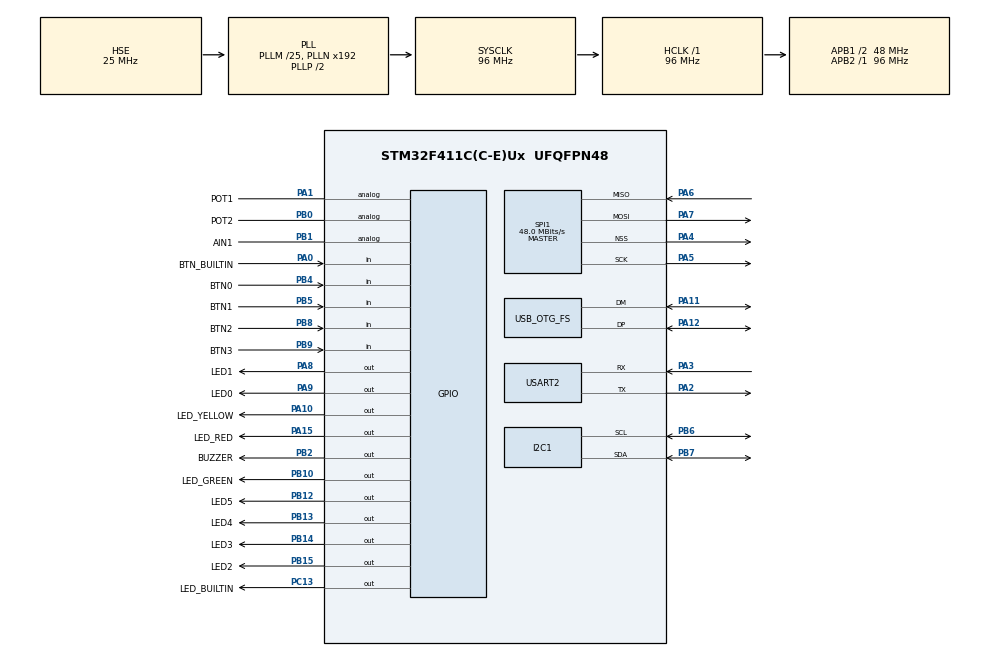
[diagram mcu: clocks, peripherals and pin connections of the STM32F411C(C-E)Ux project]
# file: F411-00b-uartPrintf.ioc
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Mcu.Family=STM32F4
Mcu.Name=STM32F411C(C-E)Ux
Mcu.Package=UFQFPN48
NVIC.PriorityGroup=NVIC_PRIORITYGROUP_4
PA0-WKUP.GPIO_Label=BTN_BUILTIN
PA0-WKUP.GPIO_PuPd=GPIO_PULLUP
PA0-WKUP.Signal=GPIO_Input
PA1.GPIO_Label=POT1
PA1.Signal=GPIO_Analog
PA10.GPIO_Label=LED_YELLOW
PA10.Signal=GPIO_Output
PA11.Mode=Device_Only
PA11.Signal=USB_OTG_FS_DM
PA12.Mode=Device_Only
PA12.Signal=USB_OTG_FS_DP
PA13.Mode=Trace_Asynchronous_SW
PA13.Signal=SYS_JTMS-SWDIO
PA14.Mode=Trace_Asynchronous_SW
PA14.Signal=SYS_JTCK-SWCLK
PA15.GPIO_Label=LED_RED
PA15.Signal=GPIO_Output
PA2.Mode=Asynchronous
PA2.Signal=USART2_TX
PA3.Mode=Asynchronous
PA3.Signal=USART2_RX
PA4.Mode=NSS_Signal_Hard_Output
PA4.Signal=SPI1_NSS
PA5.Mode=Full_Duplex_Master
PA5.Signal=SPI1_SCK
PA6.Mode=Full_Duplex_Master
PA6.Signal=SPI1_MISO
PA7.Mode=Full_Duplex_Master
PA7.Signal=SPI1_MOSI
PA8.GPIO_Label=LED1
PA8.Signal=GPIO_Output
PA9.GPIO_Label=LED0
PA9.Signal=GPIO_Output
PB0.GPIO_Label=POT2
PB0.Signal=GPIO_Analog
PB1.GPIO_Label=AIN1
PB1.Signal=GPIO_Analog
PB10.GPIO_Label=LED_GREEN
PB10.Signal=GPIO_Output
PB12.GPIO_Label=LED5
PB12.Signal=GPIO_Output
PB13.GPIO_Label=LED4
PB13.Signal=GPIO_Output
PB14.GPIO_Label=LED3
PB14.Signal=GPIO_Output
PB15.GPIO_Label=LED2
PB15.Signal=GPIO_Output
PB2.GPIO_Label=BUZZER
PB2.Signal=GPIO_Output
PB3.Mode=Trace_Asynchronous_SW
PB3.Signal=SYS_JTDO-SWO
PB4.GPIO_Label=BTN0
PB4.GPIO_PuPd=GPIO_PULLUP
PB4.Signal=GPIO_Input
PB5.GPIO_Label=BTN1
PB5.GPIO_PuPd=GPIO_PULLUP
PB5.Signal=GPIO_Input
PB6.Mode=I2C
PB6.Signal=I2C1_SCL
PB7.Mode=I2C
PB7.Signal=I2C1_SDA
PB8.GPIO_Label=BTN2
PB8.GPIO_PuPd=GPIO_PULLUP
PB8.Signal=GPIO_Input
PB9.GPIO_Label=BTN3
PB9.GPIO_PuPd=GPIO_PULLUP
PB9.Signal=GPIO_Input
PC13-ANTI_TAMP.GPIO_Label=LED_BUILTIN
PC13-ANTI_TAMP.Signal=GPIO_Output
PC14-OSC32_IN.Mode=LSE-External-Oscillator
PC14-OSC32_IN.Signal=RCC_OSC32_IN
PC15-OSC32_OUT.Mode=LSE-External-Oscillator
PC15-OSC32_OUT.Signal=RCC_OSC32_OUT
PH0\ -\ OSC_IN.Mode=HSE-External-Oscillator
PH0\ -\ OSC_IN.Signal=RCC_OSC_IN
PH1\ -\ OSC_OUT.Mode=HSE-External-Oscillator
PH1\ -\ OSC_OUT.Signal=RCC_OSC_OUT
ProjectManager.HeapSize=0x200
ProjectManager.StackSize=0x400
ProjectManager.TargetToolchain=STM32CubeIDE
RCC.48MHZClocksFreq_Value=48000000
RCC.AHBFreq_Value=96000000
RCC.APB1CLKDivider=RCC_HCLK_DIV2
RCC.APB1Freq_Value=48000000
RCC.APB1TimFreq_Value=96000000
RCC.APB2Freq_Value=96000000
RCC.APB2TimFreq_Value=96000000
RCC.CortexFreq_Value=96000000
RCC.HCLKFreq_Value=96000000
RCC.HSE_VALUE=25000000
RCC.HSI_VALUE=16000000
RCC.PLLM=25
RCC.SYSCLKFreq_VALUE=96000000
RCC.SYSCLKSource=RCC_SYSCLKSOURCE_PLLCLK
RCC.VCOOutputFreq_Value=192000000
SPI1.CalculateBaudRate=48.0 MBits/s
SPI1.Direction=SPI_DIRECTION_2LINES
SPI1.Mode=SPI_MODE_MASTER
SPI1.VirtualNSS=VM_NSSHARD
SPI1.VirtualType=VM_MASTER
USART2.VirtualMode=VM_ASYNC
USB_OTG_FS.VirtualMode=Device_Only
board=custom

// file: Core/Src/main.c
/* USER CODE BEGIN Header */
/**
  ******************************************************************************
  * @file           : main.c
  * @brief          : Main program body
  ******************************************************************************
  * @attention
  *
  * Copyright (c) 2023 STMicroelectronics.
  * All rights reserved.
  *
  * This software is licensed under terms that can be found in the LICENSE file
  * in the root directory of this software component.
  * If no LICENSE file comes with this software, it is provided AS-IS.
  *
  ******************************************************************************
  */
/* USER CODE END Header */
#include "main.h"

I2C_HandleTypeDef hi2c1;

SPI_HandleTypeDef hspi1;

UART_HandleTypeDef huart2;

PCD_HandleTypeDef hpcd_USB_OTG_FS;

void SystemClock_Config(void);
static void MX_GPIO_Init(void);
static void MX_USART2_UART_Init(void);
static void MX_I2C1_Init(void);
static void MX_SPI1_Init(void);
static void MX_USB_OTG_FS_PCD_Init(void);
/* USER CODE BEGIN PFP */
#define PUTCHAR_PROTOTYPE int __io_putchar(int ch)

PUTCHAR_PROTOTYPE
{
  /* Place your implementation of fputc here */
  /* e.g. write a character to the USART1 and Loop until the end of transmission */
  HAL_UART_Transmit(&huart2, (uint8_t *)&ch, 1, 0xFFFF);

  return ch;
}
/* USER CODE END PFP */

int main(void)
{

  /* MCU Configuration--------------------------------------------------------*/

  /* Reset of all peripherals, Initializes the Flash interface and the Systick. */
  HAL_Init();

  /* Configure the system clock */
  SystemClock_Config();

  /* Initialize all configured peripherals */
  MX_GPIO_Init();
  MX_USART2_UART_Init();
  MX_I2C1_Init();
  MX_SPI1_Init();
  MX_USB_OTG_FS_PCD_Init();
  /* USER CODE BEGIN 2 */
//  uint8_t message[]="hello world\n\r";
  /* USER CODE END 2 */

  /* Infinite loop */
  while (1)
  {

    /* USER CODE BEGIN 3 */
	  HAL_GPIO_TogglePin(LED1_GPIO_Port, LED1_Pin);
//	  HAL_UART_Transmit(&huart2, message, sizeof(message)-1	, HAL_MAX_DELAY);
	  printf("Hello dunia\n\r");
	  HAL_Delay(500);
  }
  /* USER CODE END 3 */
}

void SystemClock_Config(void)
{
  RCC_OscInitTypeDef RCC_OscInitStruct = {0};
  RCC_ClkInitTypeDef RCC_ClkInitStruct = {0};

  /** Configure the main internal regulator output voltage
  */
  __HAL_RCC_PWR_CLK_ENABLE();
  __HAL_PWR_VOLTAGESCALING_CONFIG(PWR_REGULATOR_VOLTAGE_SCALE1);

  /** Initializes the RCC Oscillators according to the specified parameters
  * in the RCC_OscInitTypeDef structure.
  */
  RCC_OscInitStruct.OscillatorType = RCC_OSCILLATORTYPE_HSE;
  RCC_OscInitStruct.HSEState = RCC_HSE_ON;
  RCC_OscInitStruct.PLL.PLLState = RCC_PLL_ON;
  RCC_OscInitStruct.PLL.PLLSource = RCC_PLLSOURCE_HSE;
  RCC_OscInitStruct.PLL.PLLM = 25;
  RCC_OscInitStruct.PLL.PLLN = 192;
  RCC_OscInitStruct.PLL.PLLP = RCC_PLLP_DIV2;
  RCC_OscInitStruct.PLL.PLLQ = 4;
  if (HAL_RCC_OscConfig(&RCC_OscInitStruct) != HAL_OK)
  {
    Error_Handler();
  }

  /** Initializes the CPU, AHB and APB buses clocks
  */
  RCC_ClkInitStruct.ClockType = RCC_CLOCKTYPE_HCLK|RCC_CLOCKTYPE_SYSCLK
                              |RCC_CLOCKTYPE_PCLK1|RCC_CLOCKTYPE_PCLK2;
  RCC_ClkInitStruct.SYSCLKSource = RCC_SYSCLKSOURCE_PLLCLK;
  RCC_ClkInitStruct.AHBCLKDivider = RCC_SYSCLK_DIV1;
  RCC_ClkInitStruct.APB1CLKDivider = RCC_HCLK_DIV2;
  RCC_ClkInitStruct.APB2CLKDivider = RCC_HCLK_DIV1;

  if (HAL_RCC_ClockConfig(&RCC_ClkInitStruct, FLASH_LATENCY_3) != HAL_OK)
  {
    Error_Handler();
  }
}

static void MX_I2C1_Init(void)
{

  hi2c1.Instance = I2C1;
  hi2c1.Init.ClockSpeed = 100000;
  hi2c1.Init.DutyCycle = I2C_DUTYCYCLE_2;
  hi2c1.Init.OwnAddress1 = 0;
  hi2c1.Init.AddressingMode = I2C_ADDRESSINGMODE_7BIT;
  hi2c1.Init.DualAddressMode = I2C_DUALADDRESS_DISABLE;
  hi2c1.Init.OwnAddress2 = 0;
  hi2c1.Init.GeneralCallMode = I2C_GENERALCALL_DISABLE;
  hi2c1.Init.NoStretchMode = I2C_NOSTRETCH_DISABLE;
  if (HAL_I2C_Init(&hi2c1) != HAL_OK)
  {
    Error_Handler();
  }

}

static void MX_SPI1_Init(void)
{

  /* SPI1 parameter configuration*/
  hspi1.Instance = SPI1;
  hspi1.Init.Mode = SPI_MODE_MASTER;
  hspi1.Init.Direction = SPI_DIRECTION_2LINES;
  hspi1.Init.DataSize = SPI_DATASIZE_8BIT;
  hspi1.Init.CLKPolarity = SPI_POLARITY_LOW;
  hspi1.Init.CLKPhase = SPI_PHASE_1EDGE;
  hspi1.Init.NSS = SPI_NSS_HARD_OUTPUT;
  hspi1.Init.BaudRatePrescaler = SPI_BAUDRATEPRESCALER_2;
  hspi1.Init.FirstBit = SPI_FIRSTBIT_MSB;
  hspi1.Init.TIMode = SPI_TIMODE_DISABLE;
  hspi1.Init.CRCCalculation = SPI_CRCCALCULATION_DISABLE;
  hspi1.Init.CRCPolynomial = 10;
  if (HAL_SPI_Init(&hspi1) != HAL_OK)
  {
    Error_Handler();
  }

}

static void MX_USART2_UART_Init(void)
{

  huart2.Instance = USART2;
  huart2.Init.BaudRate = 115200;
  huart2.Init.WordLength = UART_WORDLENGTH_8B;
  huart2.Init.StopBits = UART_STOPBITS_1;
  huart2.Init.Parity = UART_PARITY_NONE;
  huart2.Init.Mode = UART_MODE_TX_RX;
  huart2.Init.HwFlowCtl = UART_HWCONTROL_NONE;
  huart2.Init.OverSampling = UART_OVERSAMPLING_16;
  if (HAL_UART_Init(&huart2) != HAL_OK)
  {
    Error_Handler();
  }

}

static void MX_USB_OTG_FS_PCD_Init(void)
{

  hpcd_USB_OTG_FS.Instance = USB_OTG_FS;
  hpcd_USB_OTG_FS.Init.dev_endpoints = 4;
  hpcd_USB_OTG_FS.Init.speed = PCD_SPEED_FULL;
  hpcd_USB_OTG_FS.Init.dma_enable = DISABLE;
  hpcd_USB_OTG_FS.Init.phy_itface = PCD_PHY_EMBEDDED;
  hpcd_USB_OTG_FS.Init.Sof_enable = DISABLE;
  hpcd_USB_OTG_FS.Init.low_power_enable = DISABLE;
  hpcd_USB_OTG_FS.Init.lpm_enable = DISABLE;
  hpcd_USB_OTG_FS.Init.vbus_sensing_enable = DISABLE;
  hpcd_USB_OTG_FS.Init.use_dedicated_ep1 = DISABLE;
  if (HAL_PCD_Init(&hpcd_USB_OTG_FS) != HAL_OK)
  {
    Error_Handler();
  }

}

static void MX_GPIO_Init(void)
{
  GPIO_InitTypeDef GPIO_InitStruct = {0};

  /* GPIO Ports Clock Enable */
  __HAL_RCC_GPIOC_CLK_ENABLE();
  __HAL_RCC_GPIOH_CLK_ENABLE();
  __HAL_RCC_GPIOA_CLK_ENABLE();
  __HAL_RCC_GPIOB_CLK_ENABLE();

  /*Configure GPIO pin Output Level */
  HAL_GPIO_WritePin(LED_BUILTIN_GPIO_Port, LED_BUILTIN_Pin, GPIO_PIN_RESET);

  /*Configure GPIO pin Output Level */
  HAL_GPIO_WritePin(GPIOB, BUZZER_Pin|LED_GREEN_Pin|LED5_Pin|LED4_Pin
                          |LED3_Pin|LED2_Pin, GPIO_PIN_RESET);

  /*Configure GPIO pin Output Level */
  HAL_GPIO_WritePin(GPIOA, LED1_Pin|LED0_Pin|LED_YELLOW_Pin|LED_RED_Pin, GPIO_PIN_RESET);

  /*Configure GPIO pin : LED_BUILTIN_Pin */
  GPIO_InitStruct.Pin = LED_BUILTIN_Pin;
  GPIO_InitStruct.Mode = GPIO_MODE_OUTPUT_PP;
  GPIO_InitStruct.Pull = GPIO_NOPULL;
  GPIO_InitStruct.Speed = GPIO_SPEED_FREQ_LOW;
  HAL_GPIO_Init(LED_BUILTIN_GPIO_Port, &GPIO_InitStruct);

  /*Configure GPIO pin : BTN_BUILTIN_Pin */
  GPIO_InitStruct.Pin = BTN_BUILTIN_Pin;
  GPIO_InitStruct.Mode = GPIO_MODE_INPUT;
  GPIO_InitStruct.Pull = GPIO_PULLUP;
  HAL_GPIO_Init(BTN_BUILTIN_GPIO_Port, &GPIO_InitStruct);

  /*Configure GPIO pin : POT1_Pin */
  GPIO_InitStruct.Pin = POT1_Pin;
  GPIO_InitStruct.Mode = GPIO_MODE_ANALOG;
  GPIO_InitStruct.Pull = GPIO_NOPULL;
  HAL_GPIO_Init(POT1_GPIO_Port, &GPIO_InitStruct);

  /*Configure GPIO pins : POT2_Pin AIN1_Pin */
  GPIO_InitStruct.Pin = POT2_Pin|AIN1_Pin;
  GPIO_InitStruct.Mode = GPIO_MODE_ANALOG;
  GPIO_InitStruct.Pull = GPIO_NOPULL;
  HAL_GPIO_Init(GPIOB, &GPIO_InitStruct);

  /*Configure GPIO pins : BUZZER_Pin LED_GREEN_Pin LED5_Pin LED4_Pin
                           LED3_Pin LED2_Pin */
  GPIO_InitStruct.Pin = BUZZER_Pin|LED_GREEN_Pin|LED5_Pin|LED4_Pin
                          |LED3_Pin|LED2_Pin;
  GPIO_InitStruct.Mode = GPIO_MODE_OUTPUT_PP;
  GPIO_InitStruct.Pull = GPIO_NOPULL;
  GPIO_InitStruct.Speed = GPIO_SPEED_FREQ_LOW;
  HAL_GPIO_Init(GPIOB, &GPIO_InitStruct);

  /*Configure GPIO pins : LED1_Pin LED0_Pin LED_YELLOW_Pin LED_RED_Pin */
  GPIO_InitStruct.Pin = LED1_Pin|LED0_Pin|LED_YELLOW_Pin|LED_RED_Pin;
  GPIO_InitStruct.Mode = GPIO_MODE_OUTPUT_PP;
  GPIO_InitStruct.Pull = GPIO_NOPULL;
  GPIO_InitStruct.Speed = GPIO_SPEED_FREQ_LOW;
  HAL_GPIO_Init(GPIOA, &GPIO_InitStruct);

  /*Configure GPIO pins : BTN0_Pin BTN1_Pin BTN2_Pin BTN3_Pin */
  GPIO_InitStruct.Pin = BTN0_Pin|BTN1_Pin|BTN2_Pin|BTN3_Pin;
  GPIO_InitStruct.Mode = GPIO_MODE_INPUT;
  GPIO_InitStruct.Pull = GPIO_PULLUP;
  HAL_GPIO_Init(GPIOB, &GPIO_InitStruct);

}

void Error_Handler(void)
{
  __disable_irq();
  while (1)
  {
  }
}
